# ipro7 register map
Vendor: intelpro; Series: BTBLE
high-performance, 32-bit RV32IMAFC core
CPU: ipro7, little endian
Registers are 32-bit, read-write, reset 0x0 unless marked. A register's access mark holds for its fields unless they carry their own. Offsets are from the block's base; lines under a group give offsets from that group; [hi:lo] are bit positions; {n}, {i} and the like mark numbered series; 'fields as' and 'values as' point back to an identical list; <NAME> marks a mode.

## Memory map
0x30000000 GLB size 0x1000
0x30001000 RF size 0x1000
0x30004000 GPIP size 0x1000
0x30005000 SEC_DBG size 0x1000
0x30006000 TZ1 size 0x1000
0x30007000 TZ2 size 0x1000
0x30008000 EF size 0x1000
0x30008000 EF_D0 size 0x1000
0x30008000 EF_D1 size 0x1000
0x30009000 CCI size 0x1000
0x3000A000 MCU size 0x1000
0x3000B000 UART0 size 0x1000
0x3000C000 UART1 size 0x1000
0x3000D000 SPI0 size 0x1000
0x3000E000 I2C size 0x1000
0x3000F000 PWM size 0x1000
0x30010000 TIMER size 0x1000
0x30011000 IR size 0x1000
0x30012000 CKS size 0x1000
0x30013000 QDEC0 size 0x1000
0x30014000 QDEC1 size 0x1000
0x30015000 QDEC2 size 0x1000
0x30016000 KYS size 0x1000
0x30017000 I2S size 0x1000
0x30017000 AUD size 0x1000
0x3001E000 SPI1 size 0x1000
0x30040000 MMM size 0x1000
0x30041000 D2XA size 0x1000
0x30042000 D2XB size 0x1000
0x30043000 D2XC size 0x1000
0x30045000 SCALER_HYDRE size 0x1000
0x30046000 OSD_BLEND size 0x1000
0x30047000 OSD_DRAW size 0x1000
0x30048000 ISP size 0x1000
0x30049000 MJCOMBO size 0x1000
0x3004C000 AE_HIST size 0x1000
0x3004D000 TSRC size 0x1000
0x3004E000 WDR size 0x1000
0x3004F000 GAMMA size 0x1000
0x30080000 SEC_ENG size 0x1000
0x30081000 SF_CTRL size 0x1000
0x30082000 DMA size 0x1000
0x30083000 EMAC size 0x1000
0x30084000 USB size 0x1000
0x3008E000 PDS size 0x1000
0x3008F000 HBN size 0x1000
0x3008F000 AON size 0x1000
0x3C000000 M154 size 0x1000
0x3C000000 M154_MEM size 0x1000
0x3C001000 M154_AES size 0x1000

## GPIP
Base 0x30004000
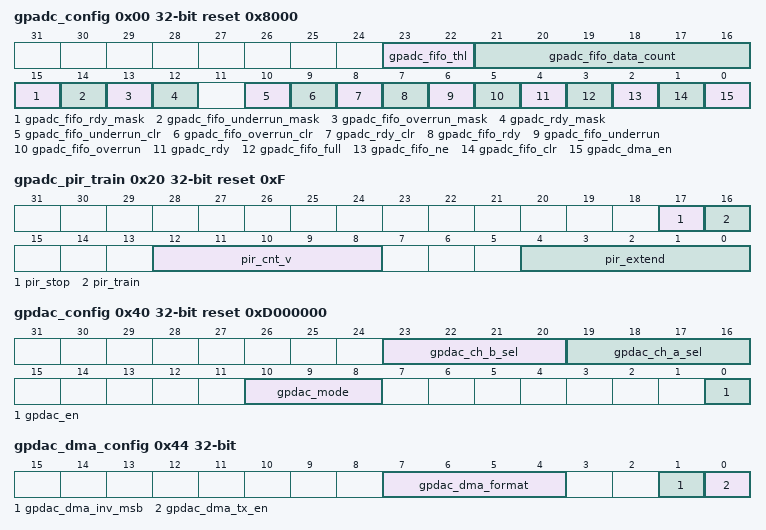
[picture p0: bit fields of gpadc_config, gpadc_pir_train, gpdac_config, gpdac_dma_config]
0x00 gpadc_config reset 0x8000 (reset mask 0xFFC0FF03)
  [23:22] gpadc_fifo_thl — fifo threshold 2'b00: 1 data 2'b01: 4 data 2'b10: 8 data 2'b11: 16 data
  [21:16] gpadc_fifo_data_count ro — fifo data number
  [15] gpadc_fifo_rdy_mask — write 1 mask
  [14] gpadc_fifo_underrun_mask — write 1 mask
  [13] gpadc_fifo_overrun_mask — write 1 mask
  [12] gpadc_rdy_mask — write 1 mask
  [10] gpadc_fifo_underrun_clr — Write 1 to clear flag
  [9] gpadc_fifo_overrun_clr — Write 1 to clear flag
  [8] gpadc_rdy_clr — Write 1 to clear flag
  [7] gpadc_fifo_rdy ro — FIFO data ready interrupt flag (fifo_data_count >= fifo_thl)
  [6] gpadc_fifo_underrun ro — FIFO underrun interrupt flag
  [5] gpadc_fifo_overrun ro — FIFO overrun interrupt flag
  [4] gpadc_rdy ro — Conversion data ready interrupt flag
  [3] gpadc_fifo_full ro — FIFO full flag
  [2] gpadc_fifo_ne ro — FIFO not empty flag
  [1] gpadc_fifo_clr — FIFO clear signal
  [0] gpadc_dma_en — GPADC DMA enbale
0x04 gpadc_dma_rdata (reset mask 0xFC000000)
  [25:0] gpadc_dma_rdata ro — GPADC finial conversion result stored in the FIFO
0x20 gpadc_pir_train reset 0xF (reset mask 0xFFFDE0FF)
  [17] pir_stop ro — PIR Training End
  [16] pir_train — PIR Training Mode
  [12:8] pir_cnt_v ro — GPADC Record Extension Counter Value
  [4:0] pir_extend — GPADC Record Extension after PIR interrupt
0x40 gpdac_config reset 0xD000000
  [23:20] gpdac_ch_b_sel — Channel B Source Select 0: Reg 1: DMA 2: DMA + Filter 3: Sin Gen 4: A (The same as channel A) 5: ~A (Inverse of channel A)
  [19:16] gpdac_ch_a_sel — Channel A Source Select 0: Reg 1: DMA 2: DMA + Filter 3: Sin Gen
  [10:8] gpdac_mode — 0:32k, 1:16k, 3:8k, 4:512k(for DMA only)
  [0] gpdac_en — GPDAC enable
0x44 gpdac_dma_config
  [7:4] gpdac_dma_format — DMA TX format (Data 10-bit) 0: ([9:0]) {A0}, {A1}, {A2}… 1: ([25:16][9:0]) {B0,A0}, {B1,A1}, {B2,A2}… 2: ([25:16][9:0]) {A1,A0}, {A3,A2}, {A5,A4}… 4: ([15:6]) {A0}, {A1}, {A2}… 5: ([31:22][15:6]) {B0,A0}, {B1,A1}, {B2,A2}… 6: ([31:22][15:6]) {A1,A0}, {A3,A2}, {A5,A4}… 8: ([31:24][23:16][15:8][7:0]) {A3,A2,A1,A0}, {A7,A6,A5,A4}… 9: ([31:24][23:16][15:8][7:0]) {B1,B0,A1,A0}, {B3,B2,A3,A2}… 10: ([31:24][23:16][15:8][7:0]) {B1,A1,B0,A0}, {B3,A3,B2,A2}… 11: ([15:8][7:0]) {B0,A0}, {B1,A1}, {B2,A2}…
  [1] gpdac_dma_inv_msb — GPDAC DMA Data Inverse MSB
  [0] gpdac_dma_tx_en — GPDAC DMA TX enable
0x48 gpdac_dma_wdata
  [31:0] gpdac_dma_wdata wo — GPDAC DMA TX data
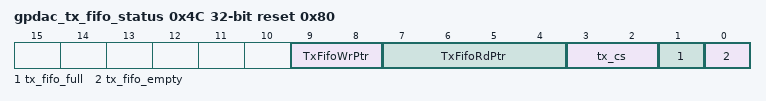
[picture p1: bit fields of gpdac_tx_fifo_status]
0x4C gpdac_tx_fifo_status reset 0x80 (reset mask 0xFFFFFC00)
  [9:8] TxFifoWrPtr ro, [7:4] TxFifoRdPtr ro, [3:2] tx_cs ro, [1] tx_fifo_full ro, [0] tx_fifo_empty ro
